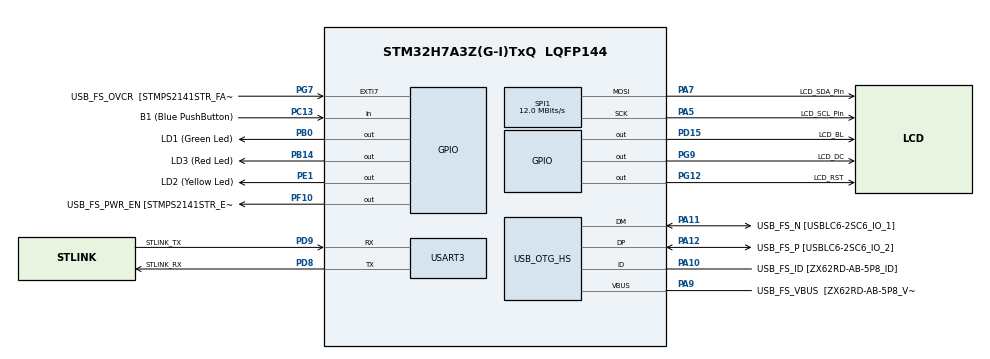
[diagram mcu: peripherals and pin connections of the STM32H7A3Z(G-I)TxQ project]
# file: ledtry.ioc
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Mcu.Family=STM32H7
Mcu.Name=STM32H7A3Z(G-I)TxQ
Mcu.Package=LQFP144
NVIC.PriorityGroup=NVIC_PRIORITYGROUP_4
PA10.GPIO_Label=USB_FS_ID [ZX62RD-AB-5P8_ID]
PA10.Mode=OTG/Dual-Role-Device-FS
PA10.Signal=USB_OTG_HS_ID
PA11.GPIO_Label=USB_FS_N [USBLC6-2SC6_IO_1]
PA11.Mode=OTG/Dual-Role-Device-FS
PA11.Signal=USB_OTG_HS_DM
PA12.GPIO_Label=USB_FS_P [USBLC6-2SC6_IO_2]
PA12.Mode=OTG/Dual-Role-Device-FS
PA12.Signal=USB_OTG_HS_DP
PA5.GPIO_Label=LCD_SCL_Pin
PA5.GPIO_Speed=GPIO_SPEED_FREQ_HIGH
PA5.Mode=TX_Only_Simplex_Unidirect_Master
PA5.Signal=SPI1_SCK
PA7.GPIO_Label=LCD_SDA_Pin
PA7.GPIO_Speed=GPIO_SPEED_FREQ_HIGH
PA7.Mode=TX_Only_Simplex_Unidirect_Master
PA7.Signal=SPI1_MOSI
PA9.GPIO_Label=USB_FS_VBUS  [ZX62RD-AB-5P8_VBUS]
PA9.Mode=Activate_VBUS_FS
PA9.Signal=USB_OTG_HS_VBUS
PB0.GPIO_Label=LD1 (Green Led)
PB0.Signal=GPIO_Output
PB14.GPIO_Label=LD3 (Red Led)
PB14.Signal=GPIO_Output
PC13.GPIO_Label=B1 (Blue PushButton)
PC13.Signal=GPIO_Input
PC14-OSC32_IN.GPIO_Label=OSC32_IN
PC14-OSC32_IN.Mode=LSE-External-Oscillator
PC14-OSC32_IN.Signal=RCC_OSC32_IN
PC15-OSC32_OUT.GPIO_Label=OSC32_OUT
PC15-OSC32_OUT.Mode=LSE-External-Oscillator
PC15-OSC32_OUT.Signal=RCC_OSC32_OUT
PD15.GPIO_Label=LCD_BL
PD15.GPIO_ModeDefaultOutputPP=GPIO_MODE_OUTPUT_PP
PD15.GPIO_PuPd=GPIO_NOPULL
PD15.GPIO_Speed=GPIO_SPEED_FREQ_LOW
PD15.PinState=GPIO_PIN_RESET
PD15.Signal=GPIO_Output
PD8.GPIO_Label=STLINK_RX
PD8.Mode=Asynchronous
PD8.Signal=USART3_TX
PD9.GPIO_Label=STLINK_TX
PD9.Mode=Asynchronous
PD9.Signal=USART3_RX
PE1.GPIO_Label=LD2 (Yellow Led)
PE1.Signal=GPIO_Output
PF10.GPIO_Label=USB_FS_PWR_EN [STMPS2141STR_EN]
PF10.Signal=GPIO_Output
PG12.GPIO_Label=LCD_RST
PG12.GPIO_ModeDefaultOutputPP=GPIO_MODE_OUTPUT_PP
PG12.GPIO_PuPd=GPIO_NOPULL
PG12.GPIO_Speed=GPIO_SPEED_FREQ_LOW
PG12.PinState=GPIO_PIN_RESET
PG12.Signal=GPIO_Output
PG7.GPIO_Label=USB_FS_OVCR  [STMPS2141STR_FAULT]
PG7.Signal=GPXTI7
PG9.GPIO_Label=LCD_DC
PG9.GPIO_ModeDefaultOutputPP=GPIO_MODE_OUTPUT_PP
PG9.GPIO_PuPd=GPIO_NOPULL
PG9.GPIO_Speed=GPIO_SPEED_FREQ_LOW
PG9.PinState=GPIO_PIN_RESET
PG9.Signal=GPIO_Output
PH0-OSC_IN.GPIO_Label=PH0-MCU
PH0-OSC_IN.Mode=HSE-External-Clock-Source
PH0-OSC_IN.Signal=RCC_OSC_IN
PH1-OSC_OUT.GPIO_Label=PH1-MCU
PH1-OSC_OUT.Signal=RCC_OSC_OUT
ProjectManager.HeapSize=0x200
ProjectManager.StackSize=0x400
ProjectManager.TargetToolchain=STM32CubeIDE
RCC.ADCFreq_Value=16125000
RCC.APB1Freq_Value=96000000
RCC.APB2Freq_Value=96000000
RCC.APB3Freq_Value=96000000
RCC.APB4Freq_Value=96000000
RCC.CortexFreq_Value=96000000
RCC.DIVM1=1
RCC.DIVM3=1
RCC.DIVN1=24
RCC.DIVN3=24
RCC.DIVQ1=4
RCC.HCLKFreq_Value=96000000
RCC.HSE_VALUE=8000000
RCC.PLLFRACN=0
RCC.PLLSourceVirtual=RCC_PLLSOURCE_HSE
RCC.PWR_Regulator_Voltage_Scale=PWR_REGULATOR_VOLTAGE_SCALE0
RCC.SYSCLKFreq_VALUE=96000000
RCC.SYSCLKSource=RCC_SYSCLKSOURCE_PLLCLK
RCC.SupplySource=PWR_DIRECT_SMPS_SUPPLY
RCC.USBCLockSelection=RCC_USBCLKSOURCE_HSI48
RCC.USBFreq_Value=48000000
SPI1.BaudRatePrescaler=SPI_BAUDRATEPRESCALER_4
SPI1.CLKPhase=SPI_PHASE_2EDGE
SPI1.CLKPolarity=SPI_POLARITY_HIGH
SPI1.CalculateBaudRate=12.0 MBits/s
SPI1.DataSize=SPI_DATASIZE_8BIT
SPI1.Direction=SPI_DIRECTION_2LINES_TXONLY
SPI1.Mode=SPI_MODE_MASTER
SPI1.VirtualType=VM_MASTER
USART3.VirtualMode-Asynchronous=VM_ASYNC
board=NUCLEO-H7A3ZI-Q

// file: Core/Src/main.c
/* USER CODE BEGIN Header */
/**
  ******************************************************************************
  * @file           : main.c
  * @brief          : Main program body
  ******************************************************************************
  * @attention
  *
  * Copyright (c) 2023 STMicroelectronics.
  * All rights reserved.
  *
  * This software is licensed under terms that can be found in the LICENSE file
  * in the root directory of this software component.
  * If no LICENSE file comes with this software, it is provided AS-IS.
  *
  ******************************************************************************
  */
/* USER CODE END Header */
#include "main.h"
#include "spi.h"
#include "usart.h"
#include "usb_otg.h"
#include "gpio.h"

void SystemClock_Config(void);

int main(void)
{

  /* MCU Configuration--------------------------------------------------------*/

  /* Reset of all peripherals, Initializes the Flash interface and the Systick. */
  HAL_Init();

  /* Configure the system clock */
  SystemClock_Config();

  /* Initialize all configured peripherals */
  MX_GPIO_Init();
  MX_USART3_UART_Init();
  MX_USB_OTG_HS_USB_Init();
  MX_SPI1_Init();
  /* USER CODE BEGIN 2 */
  LCD_Init();
  LCD_Fill(0,0,LCD_W/2,LCD_H/2,RED);
  float t=0;
  /* USER CODE END 2 */

  /* Infinite loop */
  while (1)
  {

    /* USER CODE BEGIN 3 */
	  HAL_GPIO_WritePin(LD1_GPIO_Port, LD1_Pin, GPIO_PIN_SET);
	  HAL_GPIO_WritePin(LD2_GPIO_Port, LD2_Pin, GPIO_PIN_SET);
	  HAL_GPIO_WritePin(LD3_GPIO_Port, LD3_Pin, GPIO_PIN_SET);
    LCD_ShowString(24,30,"LCD_W:",RED,WHITE,16,0);
		LCD_ShowIntNum(72,30,LCD_W,3,RED,WHITE,16);
		LCD_ShowString(24,50,"LCD_H:",RED,WHITE,16,0);
		LCD_ShowIntNum(72,50,LCD_H,3,RED,WHITE,16);
		LCD_ShowFloatNum1(20,80,t,4,RED,WHITE,16);
    t+=0.11;
  }
  /* USER CODE END 3 */
}

void SystemClock_Config(void)
{
  RCC_OscInitTypeDef RCC_OscInitStruct = {0};
  RCC_ClkInitTypeDef RCC_ClkInitStruct = {0};

  /*AXI clock gating */
  RCC->CKGAENR = 0xFFFFFFFF;

  /** Supply configuration update enable
  */
  HAL_PWREx_ConfigSupply(PWR_DIRECT_SMPS_SUPPLY);

  /** Configure the main internal regulator output voltage
  */
  __HAL_PWR_VOLTAGESCALING_CONFIG(PWR_REGULATOR_VOLTAGE_SCALE0);

  while(!__HAL_PWR_GET_FLAG(PWR_FLAG_VOSRDY)) {}

  /** Initializes the RCC Oscillators according to the specified parameters
  * in the RCC_OscInitTypeDef structure.
  */
  RCC_OscInitStruct.OscillatorType = RCC_OSCILLATORTYPE_HSI48|RCC_OSCILLATORTYPE_HSE;
  RCC_OscInitStruct.HSEState = RCC_HSE_BYPASS;
  RCC_OscInitStruct.HSI48State = RCC_HSI48_ON;
  RCC_OscInitStruct.PLL.PLLState = RCC_PLL_ON;
  RCC_OscInitStruct.PLL.PLLSource = RCC_PLLSOURCE_HSE;
  RCC_OscInitStruct.PLL.PLLM = 1;
  RCC_OscInitStruct.PLL.PLLN = 24;
  RCC_OscInitStruct.PLL.PLLP = 2;
  RCC_OscInitStruct.PLL.PLLQ = 4;
  RCC_OscInitStruct.PLL.PLLR = 2;
  RCC_OscInitStruct.PLL.PLLRGE = RCC_PLL1VCIRANGE_3;
  RCC_OscInitStruct.PLL.PLLVCOSEL = RCC_PLL1VCOWIDE;
  RCC_OscInitStruct.PLL.PLLFRACN = 0;
  if (HAL_RCC_OscConfig(&RCC_OscInitStruct) != HAL_OK)
  {
    Error_Handler();
  }

  /** Initializes the CPU, AHB and APB buses clocks
  */
  RCC_ClkInitStruct.ClockType = RCC_CLOCKTYPE_HCLK|RCC_CLOCKTYPE_SYSCLK
                              |RCC_CLOCKTYPE_PCLK1|RCC_CLOCKTYPE_PCLK2
                              |RCC_CLOCKTYPE_D3PCLK1|RCC_CLOCKTYPE_D1PCLK1;
  RCC_ClkInitStruct.SYSCLKSource = RCC_SYSCLKSOURCE_PLLCLK;
  RCC_ClkInitStruct.SYSCLKDivider = RCC_SYSCLK_DIV1;
  RCC_ClkInitStruct.AHBCLKDivider = RCC_HCLK_DIV1;
  RCC_ClkInitStruct.APB3CLKDivider = RCC_APB3_DIV1;
  RCC_ClkInitStruct.APB1CLKDivider = RCC_APB1_DIV1;
  RCC_ClkInitStruct.APB2CLKDivider = RCC_APB2_DIV1;
  RCC_ClkInitStruct.APB4CLKDivider = RCC_APB4_DIV1;

  if (HAL_RCC_ClockConfig(&RCC_ClkInitStruct, FLASH_LATENCY_2) != HAL_OK)
  {
    Error_Handler();
  }
}

void Error_Handler(void)
{
  __disable_irq();
  while (1)
  {
  }
}
